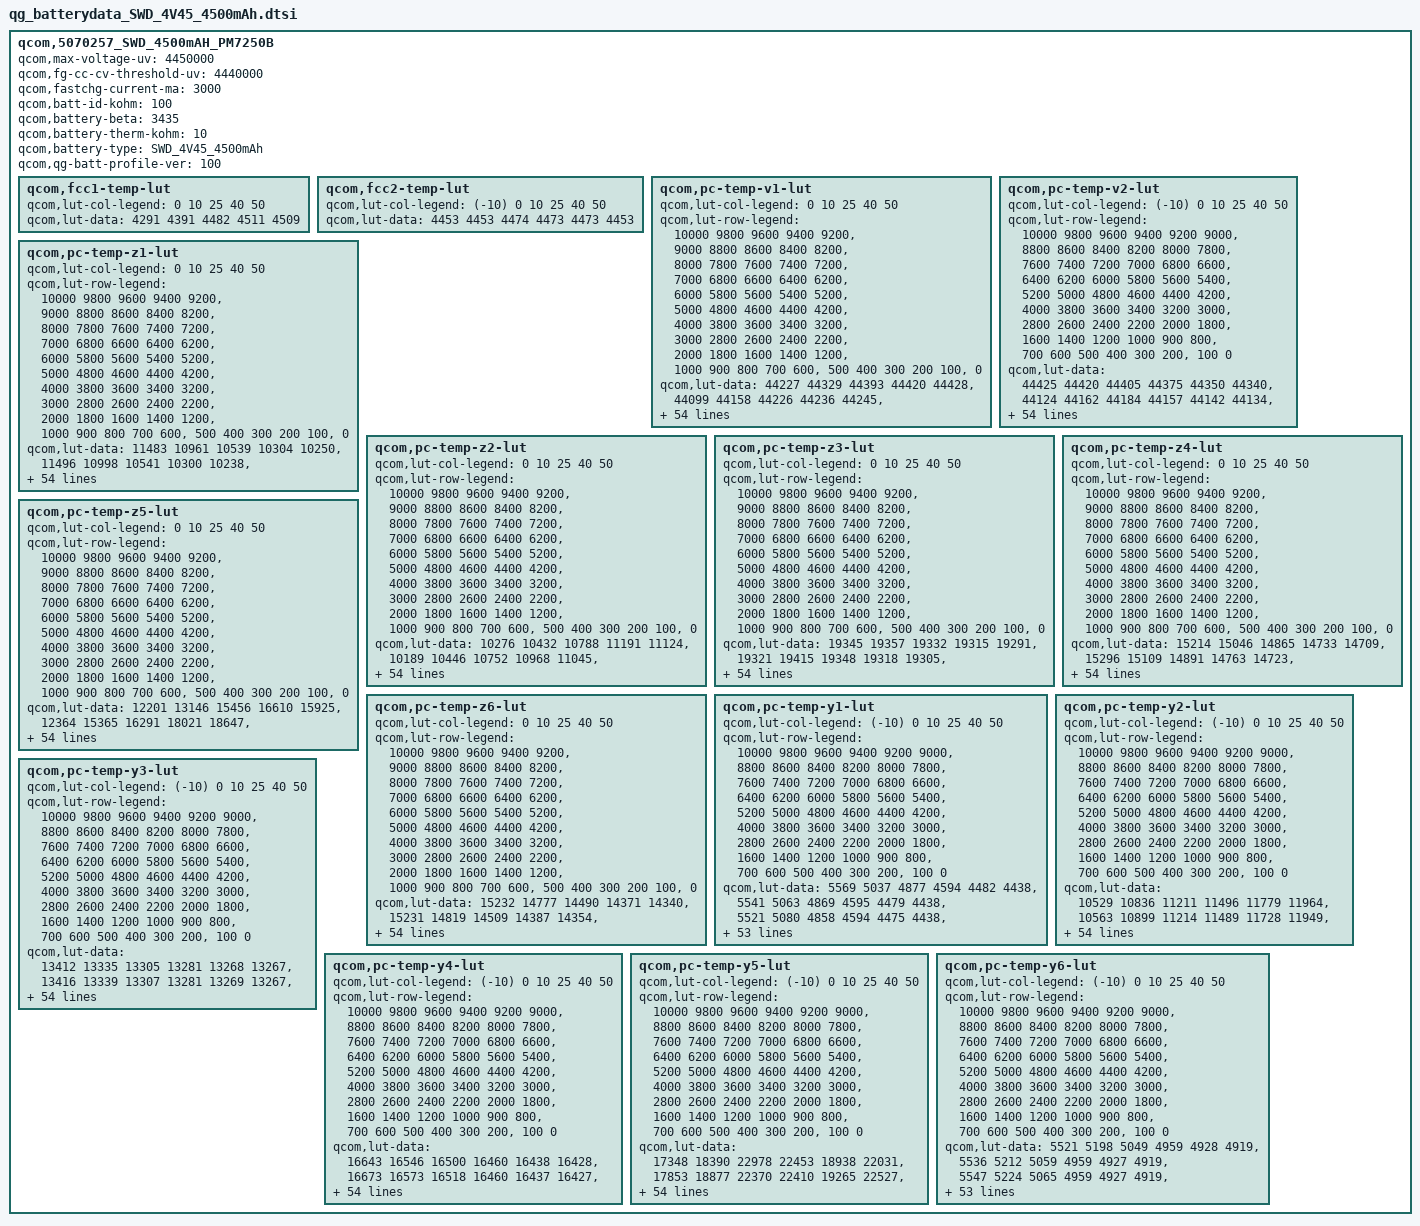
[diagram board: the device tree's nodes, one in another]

qcom,5070257_SWD_4500mAH_PM7250B {
    /* 5070257_SWD_4500mAH_PM7250B_averaged_MasterSlave_Mar23th2021 */
    qcom,max-voltage-uv = <4450000>;
    qcom,fg-cc-cv-threshold-uv = <4440000>;
    qcom,fastchg-current-ma = <3000>;
    qcom,batt-id-kohm = <100>;
    qcom,battery-beta = <3435>;
    qcom,battery-therm-kohm = <10>;
    qcom,battery-type = "SWD_4V45_4500mAh";
    qcom,qg-batt-profile-ver = <100>;

	qcom,fcc1-temp-lut {
		qcom,lut-col-legend = <0 10 25 40 50>;
		qcom,lut-data = <4291 4391 4482 4511 4509>;
	};

	qcom,fcc2-temp-lut {
		qcom,lut-col-legend = <(-10) 0 10 25 40 50>;
		qcom,lut-data = <4453 4453 4474 4473 4473 4453>;
	};

	qcom,pc-temp-v1-lut {
		qcom,lut-col-legend = <0 10 25 40 50>;
		qcom,lut-row-legend = <10000 9800 9600 9400 9200>,
			<9000 8800 8600 8400 8200>,
			<8000 7800 7600 7400 7200>,
			<7000 6800 6600 6400 6200>,
			<6000 5800 5600 5400 5200>,
			<5000 4800 4600 4400 4200>,
			<4000 3800 3600 3400 3200>,
			<3000 2800 2600 2400 2200>,
			<2000 1800 1600 1400 1200>,
			<1000 900 800 700 600>,
			<500 400 300 200 100>,
			<0>;
		qcom,lut-data = <44227 44329 44393 44420 44428>,
			<44099 44158 44226 44236 44245>,
			<43880 43973 44040 44054 44061>,
			<43653 43778 43849 43867 43876>,
			<43434 43574 43653 43675 43689>,
			<43208 43357 43446 43473 43492>,
			<42979 43129 43222 43258 43280>,
			<42744 42896 42989 43030 43054>,
			<42510 42658 42751 42797 42823>,
			<42277 42417 42508 42554 42583>,
			<42046 42178 42265 42310 42343>,
			<41821 41940 42024 42069 42105>,
			<41600 41709 41785 41830 41868>,
			<41386 41483 41551 41595 41634>,
			<41179 41264 41324 41366 41403>,
			<40978 41054 41104 41142 41177>,
			<40777 40850 40892 40924 40957>,
			<40574 40651 40686 40713 40744>,
			<40371 40464 40491 40512 40542>,
			<40169 40267 40307 40327 40354>,
			<39970 40016 40104 40132 40158>,
			<39769 39721 39849 39893 39925>,
			<39546 39485 39586 39634 39677>,
			<39314 39326 39379 39416 39460>,
			<39148 39192 39206 39231 39265>,
			<39044 39061 39055 39070 39095>,
			<38960 38937 38922 38931 38952>,
			<38869 38824 38803 38808 38827>,
			<38776 38721 38693 38694 38710>,
			<38689 38627 38591 38587 38600>,
			<38612 38541 38497 38489 38499>,
			<38539 38462 38408 38397 38405>,
			<38475 38391 38328 38313 38317>,
			<38416 38327 38259 38237 38237>,
			<38363 38271 38200 38170 38165>,
			<38317 38220 38143 38103 38090>,
			<38277 38179 38087 38031 38003>,
			<38226 38132 38029 37953 37908>,
			<38143 38056 37953 37866 37812>,
			<38036 37948 37854 37767 37713>,
			<37918 37829 37742 37657 37604>,
			<37779 37695 37616 37532 37475>,
			<37620 37545 37474 37391 37329>,
			<37437 37368 37299 37221 37162>,
			<37325 37213 37152 37087 37029>,
			<37230 37127 37068 37014 36958>,
			<37194 37103 37050 36995 36943>,
			<37165 37080 37029 36980 36928>,
			<37133 37057 37002 36957 36907>,
			<37053 36966 36895 36823 36803>,
			<36783 36648 36551 36475 36482>,
			<36324 36181 36079 36007 36042>,
			<35744 35581 35470 35403 35474>,
			<34969 34765 34644 34582 34715>,
			<33763 33484 33350 33316 33590>,
			<30000 30000 30000 30000 30000>;
	};

	qcom,pc-temp-v2-lut {
		qcom,lut-col-legend = <(-10) 0 10 25 40 50>;
		qcom,lut-row-legend = <10000 9800 9600 9400 9200 9000>,
			<8800 8600 8400 8200 8000 7800>,
			<7600 7400 7200 7000 6800 6600>,
			<6400 6200 6000 5800 5600 5400>,
			<5200 5000 4800 4600 4400 4200>,
			<4000 3800 3600 3400 3200 3000>,
			<2800 2600 2400 2200 2000 1800>,
			<1600 1400 1200 1000 900 800>,
			<700 600 500 400 300 200>,
			<100 0>;
		qcom,lut-data = <44425 44420 44405 44375 44350 44340>,
			<44124 44162 44184 44157 44142 44134>,
			<43845 43921 43969 43944 43936 43929>,
			<43590 43700 43763 43736 43732 43727>,
			<43361 43500 43567 43537 43533 43529>,
			<43135 43295 43363 43330 43327 43324>,
			<42899 43069 43141 43107 43106 43104>,
			<42660 42832 42907 42873 42874 42876>,
			<42416 42594 42670 42636 42640 42644>,
			<42165 42351 42429 42394 42399 42405>,
			<41913 42108 42187 42152 42158 42166>,
			<41654 41868 41948 41912 41920 41929>,
			<41400 41631 41710 41674 41684 41694>,
			<41203 41397 41476 41442 41451 41463>,
			<41066 41165 41246 41215 41223 41237>,
			<40916 40945 41022 40994 41001 41015>,
			<40671 40760 40810 40779 40787 40800>,
			<40351 40589 40605 40569 40579 40591>,
			<40056 40377 40392 40367 40379 40391>,
			<39784 40093 40175 40178 40192 40207>,
			<39528 39800 39946 39975 39993 40013>,
			<39289 39546 39684 39719 39741 39767>,
			<39065 39309 39412 39435 39461 39488>,
			<38861 39102 39190 39209 39238 39262>,
			<38666 38920 39009 39032 39062 39088>,
			<38499 38758 38850 38878 38909 38938>,
			<38378 38614 38710 38740 38774 38802>,
			<38281 38484 38584 38617 38653 38680>,
			<38201 38360 38467 38505 38541 38566>,
			<38135 38233 38357 38401 38438 38459>,
			<38078 38121 38256 38305 38343 38360>,
			<38019 38039 38162 38214 38254 38271>,
			<37964 37974 38075 38129 38172 38190>,
			<37907 37919 37994 38048 38089 38105>,
			<37852 37876 37920 37975 38006 38015>,
			<37794 37837 37851 37900 37917 37917>,
			<37728 37794 37789 37809 37808 37802>,
			<37655 37751 37732 37708 37684 37666>,
			<37574 37695 37662 37610 37572 37542>,
			<37482 37616 37577 37519 37477 37443>,
			<37377 37513 37476 37424 37379 37348>,
			<37255 37381 37354 37313 37264 37234>,
			<37111 37205 37211 37187 37134 37102>,
			<36981 37030 37047 37029 36976 36954>,
			<36867 36877 36920 36912 36871 36831>,
			<36781 36797 36858 36875 36845 36803>,
			<36741 36771 36835 36860 36830 36790>,
			<36696 36736 36804 36835 36809 36772>,
			<36633 36692 36756 36793 36768 36738>,
			<36497 36576 36626 36673 36623 36629>,
			<36199 36288 36287 36336 36258 36295>,
			<35750 35841 35780 35838 35755 35826>,
			<35122 35227 35113 35196 35109 35227>,
			<34249 34398 34203 34344 34230 34434>,
			<32871 33127 32802 33051 32965 33306>,
			<29691 30594 29626 29434 29627 31317>;
	};

	qcom,pc-temp-z1-lut {
		qcom,lut-col-legend = <0 10 25 40 50>;
		qcom,lut-row-legend = <10000 9800 9600 9400 9200>,
			<9000 8800 8600 8400 8200>,
			<8000 7800 7600 7400 7200>,
			<7000 6800 6600 6400 6200>,
			<6000 5800 5600 5400 5200>,
			<5000 4800 4600 4400 4200>,
			<4000 3800 3600 3400 3200>,
			<3000 2800 2600 2400 2200>,
			<2000 1800 1600 1400 1200>,
			<1000 900 800 700 600>,
			<500 400 300 200 100>,
			<0>;
		qcom,lut-data = <11483 10961 10539 10304 10250>,
			<11496 10998 10541 10300 10238>,
			<11471 10996 10529 10298 10238>,
			<11463 10980 10520 10295 10237>,
			<11466 10960 10512 10291 10236>,
			<11467 10938 10504 10288 10234>,
			<11457 10917 10493 10285 10233>,
			<11431 10907 10483 10282 10232>,
			<11403 10900 10478 10280 10231>,
			<11375 10895 10475 10278 10229>,
			<11343 10888 10472 10276 10227>,
			<11326 10881 10469 10274 10227>,
			<11319 10878 10466 10273 10227>,
			<11314 10878 10464 10272 10227>,
			<11313 10877 10462 10271 10226>,
			<11314 10872 10461 10271 10225>,
			<11315 10865 10460 10271 10225>,
			<11313 10861 10460 10271 10227>,
			<11309 10859 10460 10271 10228>,
			<11310 10857 10462 10271 10227>,
			<11314 10856 10463 10270 10227>,
			<11318 10859 10464 10271 10227>,
			<11315 10862 10465 10271 10228>,
			<11309 10863 10467 10272 10228>,
			<11306 10864 10472 10274 10229>,
			<11313 10864 10477 10276 10229>,
			<11320 10862 10481 10278 10231>,
			<11320 10861 10483 10280 10234>,
			<11316 10867 10486 10282 10236>,
			<11313 10874 10490 10284 10236>,
			<11321 10875 10493 10286 10237>,
			<11337 10876 10497 10288 10238>,
			<11340 10879 10500 10291 10240>,
			<11329 10884 10504 10293 10242>,
			<11318 10891 10508 10296 10243>,
			<11321 10895 10512 10298 10245>,
			<11333 10899 10517 10301 10248>,
			<11341 10903 10523 10304 10250>,
			<11339 10907 10528 10307 10252>,
			<11336 10917 10533 10309 10253>,
			<11338 10920 10537 10311 10254>,
			<11344 10914 10539 10310 10255>,
			<11356 10911 10542 10310 10255>,
			<11376 10928 10547 10312 10255>,
			<11368 10938 10556 10315 10256>,
			<11372 10949 10558 10316 10257>,
			<11374 10929 10559 10315 10255>,
			<11360 10940 10557 10316 10255>,
			<11378 10948 10560 10318 10257>,
			<11405 10957 10568 10320 10259>,
			<11404 10939 10566 10321 10259>,
			<11405 10972 10576 10325 10260>,
			<11423 10970 10586 10329 10264>,
			<11416 10967 10587 10333 10267>,
			<11416 10967 10587 10333 10267>,
			<11416 10967 10587 10333 10267>;
	};

	qcom,pc-temp-z2-lut {
		qcom,lut-col-legend = <0 10 25 40 50>;
		qcom,lut-row-legend = <10000 9800 9600 9400 9200>,
			<9000 8800 8600 8400 8200>,
			<8000 7800 7600 7400 7200>,
			<7000 6800 6600 6400 6200>,
			<6000 5800 5600 5400 5200>,
			<5000 4800 4600 4400 4200>,
			<4000 3800 3600 3400 3200>,
			<3000 2800 2600 2400 2200>,
			<2000 1800 1600 1400 1200>,
			<1000 900 800 700 600>,
			<500 400 300 200 100>,
			<0>;
		qcom,lut-data = <10276 10432 10788 11191 11124>,
			<10189 10446 10752 10968 11045>,
			<10279 10474 10771 10906 11065>,
			<10336 10510 10759 10906 11050>,
			<10335 10522 10731 10892 10973>,
			<10332 10499 10722 10876 10916>,
			<10323 10462 10717 10864 10924>,
			<10301 10439 10707 10843 10940>,
			<10279 10423 10696 10828 10947>,
			<10264 10417 10681 10833 10959>,
			<10252 10431 10670 10850 10972>,
			<10250 10452 10673 10859 10977>,
			<10272 10460 10687 10859 10979>,
			<10299 10461 10692 10860 10988>,
			<10314 10463 10688 10875 11017>,
			<10324 10475 10684 10895 11041>,
			<10333 10493 10683 10917 11046>,
			<10340 10498 10685 10939 11049>,
			<10346 10501 10693 10941 11058>,
			<10352 10503 10708 10933 11075>,
			<10359 10507 10713 10930 11091>,
			<10363 10509 10717 10957 11120>,
			<10354 10505 10725 10993 11156>,
			<10335 10499 10743 10985 11138>,
			<10327 10500 10778 10877 11000>,
			<10333 10507 10792 10777 10884>,
			<10344 10517 10749 10749 10854>,
			<10352 10519 10690 10736 10836>,
			<10361 10508 10679 10742 10838>,
			<10369 10496 10681 10763 10876>,
			<10374 10496 10685 10785 10925>,
			<10379 10511 10702 10803 10970>,
			<10386 10529 10722 10826 11021>,
			<10398 10544 10734 10865 11071>,
			<10409 10558 10753 10938 11127>,
			<10410 10562 10768 10991 11180>,
			<10411 10561 10782 11008 11241>,
			<10412 10560 10803 11023 11297>,
			<10424 10574 10829 11048 11304>,
			<10438 10601 10876 11105 11280>,
			<10439 10610 10902 11141 11260>,
			<10429 10583 10890 11110 11253>,
			<10426 10569 10871 11066 11236>,
			<10435 10577 10852 11028 11153>,
			<11496 10658 10865 11038 11127>,
			<16946 10662 10864 11045 11112>,
			<16875 10644 10839 11067 11205>,
			<18706 10638 10782 11122 11277>,
			<18966 10661 10795 11145 11438>,
			<17819 10699 10840 11038 11138>,
			<17294 10780 10804 10876 10990>,
			<16141 10854 10728 10822 10887>,
			<15024 10936 10675 10769 10866>,
			<13292 10886 10696 10710 10806>,
			<13292 10886 10696 10710 10806>,
			<13292 10886 10696 10710 10806>;
	};

	qcom,pc-temp-z3-lut {
		qcom,lut-col-legend = <0 10 25 40 50>;
		qcom,lut-row-legend = <10000 9800 9600 9400 9200>,
			<9000 8800 8600 8400 8200>,
			<8000 7800 7600 7400 7200>,
			<7000 6800 6600 6400 6200>,
			<6000 5800 5600 5400 5200>,
			<5000 4800 4600 4400 4200>,
			<4000 3800 3600 3400 3200>,
			<3000 2800 2600 2400 2200>,
			<2000 1800 1600 1400 1200>,
			<1000 900 800 700 600>,
			<500 400 300 200 100>,
			<0>;
		qcom,lut-data = <19345 19357 19332 19315 19291>,
			<19321 19415 19348 19318 19305>,
			<19482 19449 19368 19328 19316>,
			<19575 19471 19380 19337 19321>,
			<19598 19484 19388 19343 19323>,
			<19612 19492 19392 19345 19323>,
			<19617 19497 19392 19343 19323>,
			<19620 19497 19392 19337 19323>,
			<19622 19495 19390 19334 19322>,
			<19623 19493 19384 19333 19321>,
			<19622 19488 19379 19333 19319>,
			<19620 19484 19377 19332 19316>,
			<19612 19480 19375 19330 19312>,
			<19601 19477 19373 19327 19310>,
			<19594 19474 19370 19323 19309>,
			<19588 19470 19366 19319 19308>,
			<19586 19467 19363 19317 19307>,
			<19586 19463 19360 19317 19306>,
			<19587 19459 19359 19316 19305>,
			<19589 19457 19360 19314 19303>,
			<19590 19463 19360 19313 19302>,
			<19591 19479 19360 19315 19306>,
			<19592 19485 19361 19321 19315>,
			<19593 19470 19365 19327 19322>,
			<19593 19453 19379 19336 19329>,
			<19589 19456 19389 19341 19332>,
			<19584 19476 19392 19341 19330>,
			<19584 19487 19394 19340 19325>,
			<19585 19484 19392 19339 19322>,
			<19586 19478 19386 19335 19318>,
			<19584 19474 19380 19330 19314>,
			<19580 19469 19378 19328 19311>,
			<19577 19466 19376 19325 19309>,
			<19573 19463 19372 19322 19306>,
			<19570 19460 19368 19319 19303>,
			<19567 19459 19366 19317 19301>,
			<19565 19458 19367 19318 19302>,
			<19562 19456 19368 19319 19304>,
			<19555 19453 19367 19321 19306>,
			<19547 19446 19365 19323 19308>,
			<19541 19441 19362 19325 19311>,
			<19538 19439 19359 19323 19313>,
			<19533 19436 19357 19320 19314>,
			<19524 19429 19356 19323 19314>,
			<19297 19414 19349 19319 19312>,
			<19257 19405 19345 19313 19306>,
			<19257 19403 19338 19311 19297>,
			<19256 19403 19337 19307 19295>,
			<19256 19390 19336 19301 19292>,
			<19256 19389 19338 19315 19301>,
			<19256 19380 19350 19319 19306>,
			<19257 19361 19353 19321 19305>,
			<19257 19340 19355 19322 19306>,
			<19257 19331 19344 19323 19308>,
			<19257 19331 19344 19323 19308>,
			<19257 19331 19344 19323 19308>;
	};

	qcom,pc-temp-z4-lut {
		qcom,lut-col-legend = <0 10 25 40 50>;
		qcom,lut-row-legend = <10000 9800 9600 9400 9200>,
			<9000 8800 8600 8400 8200>,
			<8000 7800 7600 7400 7200>,
			<7000 6800 6600 6400 6200>,
			<6000 5800 5600 5400 5200>,
			<5000 4800 4600 4400 4200>,
			<4000 3800 3600 3400 3200>,
			<3000 2800 2600 2400 2200>,
			<2000 1800 1600 1400 1200>,
			<1000 900 800 700 600>,
			<500 400 300 200 100>,
			<0>;
		qcom,lut-data = <15214 15046 14865 14733 14709>,
			<15296 15109 14891 14763 14723>,
			<15277 15102 14882 14761 14722>,
			<15250 15045 14861 14752 14719>,
			<15182 14980 14821 14731 14704>,
			<15093 14925 14785 14710 14688>,
			<15023 14875 14753 14698 14678>,
			<14962 14834 14728 14690 14670>,
			<14911 14796 14718 14684 14664>,
			<14871 14769 14714 14678 14661>,
			<14838 14756 14708 14672 14658>,
			<14812 14747 14702 14667 14655>,
			<14789 14742 14695 14662 14653>,
			<14773 14738 14689 14658 14649>,
			<14770 14736 14684 14655 14644>,
			<14769 14732 14681 14652 14640>,
			<14768 14729 14679 14647 14635>,
			<14774 14729 14677 14642 14630>,
			<14786 14732 14674 14639 14627>,
			<14795 14739 14672 14637 14624>,
			<14802 14761 14673 14637 14623>,
			<14811 14812 14715 14658 14637>,
			<14838 14842 14771 14698 14663>,
			<14882 14848 14777 14708 14669>,
			<14899 14851 14763 14701 14666>,
			<14881 14842 14747 14692 14662>,
			<14856 14805 14731 14683 14660>,
			<14839 14778 14716 14674 14656>,
			<14826 14769 14708 14668 14653>,
			<14818 14763 14703 14664 14650>,
			<14816 14762 14700 14660 14646>,
			<14814 14762 14698 14656 14643>,
			<14813 14763 14697 14653 14640>,
			<14813 14764 14697 14652 14638>,
			<14812 14765 14698 14652 14637>,
			<14810 14766 14700 14653 14636>,
			<14806 14763 14704 14659 14643>,
			<14802 14760 14710 14671 14655>,
			<14796 14757 14710 14673 14657>,
			<14787 14754 14710 14670 14652>,
			<14775 14747 14708 14667 14647>,
			<14756 14732 14698 14661 14642>,
			<14735 14715 14684 14656 14638>,
			<14714 14701 14676 14652 14637>,
			<14870 14671 14662 14646 14633>,
			<14891 14654 14646 14635 14626>,
			<14887 14645 14638 14627 14625>,
			<14884 14639 14628 14622 14617>,
			<14878 14645 14625 14620 14613>,
			<14876 14649 14630 14617 14612>,
			<14878 14663 14624 14618 14614>,
			<14882 14685 14620 14616 14615>,
			<14883 14708 14618 14615 14614>,
			<14886 14721 14628 14616 14612>,
			<14886 14721 14628 14616 14612>,
			<14886 14721 14628 14616 14612>;
	};

	qcom,pc-temp-z5-lut {
		qcom,lut-col-legend = <0 10 25 40 50>;
		qcom,lut-row-legend = <10000 9800 9600 9400 9200>,
			<9000 8800 8600 8400 8200>,
			<8000 7800 7600 7400 7200>,
			<7000 6800 6600 6400 6200>,
			<6000 5800 5600 5400 5200>,
			<5000 4800 4600 4400 4200>,
			<4000 3800 3600 3400 3200>,
			<3000 2800 2600 2400 2200>,
			<2000 1800 1600 1400 1200>,
			<1000 900 800 700 600>,
			<500 400 300 200 100>,
			<0>;
		qcom,lut-data = <12201 13146 15456 16610 15925>,
			<12364 15365 16291 18021 18647>,
			<15215 17021 17797 19534 21225>,
			<17512 18271 18664 20627 22012>,
			<18779 19303 19192 21380 22112>,
			<19845 20239 19853 21745 22229>,
			<20990 21139 21014 21700 22927>,
			<22148 22184 21986 21480 24107>,
			<23424 23524 22037 21416 24570>,
			<24991 24890 21763 21907 24723>,
			<26743 26070 21624 22568 24779>,
			<28473 27104 22052 23052 24223>,
			<30581 27749 22779 23456 23170>,
			<32189 28164 23215 23507 22980>,
			<32476 28524 23445 22827 23715>,
			<32541 28943 23406 22178 24600>,
			<32677 29302 23234 22709 25627>,
			<34836 29295 23347 23918 27104>,
			<37933 28658 24167 24754 28366>,
			<38409 28071 25812 25382 29729>,
			<36669 30916 26653 25691 30499>,
			<35156 37924 25006 23766 28084>,
			<35209 40389 22323 20293 23616>,
			<35545 32530 21433 19415 22556>,
			<35577 23441 21090 19597 22892>,
			<33964 23095 21014 19915 23136>,
			<32074 26714 22436 20951 23318>,
			<32332 30188 24850 22658 23694>,
			<34946 32383 26470 23798 23874>,
			<37600 34252 27686 24515 24367>,
			<39353 35907 29161 25348 24978>,
			<40892 37484 31956 26909 25819>,
			<41778 38662 34715 28838 27012>,
			<42405 39408 35582 30241 28052>,
			<42768 39964 35988 31461 29137>,
			<42739 40040 36217 32068 29704>,
			<42549 39753 36341 31219 28615>,
			<42322 39318 36419 29767 26762>,
			<41786 38239 35752 29503 26649>,
			<41146 36084 32558 29932 28796>,
			<40947 34948 30175 30245 31634>,
			<40919 34742 29770 29679 35540>,
			<40996 34365 29480 29046 38344>,
			<41297 32504 27986 29599 37333>,
			<15996 36567 27844 27311 33293>,
			<11520 36362 30829 26536 28949>,
			<11465 35846 28815 30108 24360>,
			<11413 38680 33083 33526 29376>,
			<11381 27120 33248 29161 32387>,
			<11386 25819 27961 38977 38496>,
			<11427 20698 33144 36361 37762>,
			<11382 16616 35473 39815 35624>,
			<11352 14381 37768 40149 34964>,
			<11276 13730 28173 39394 36724>,
			<11276 13730 28173 39394 36724>,
			<11276 13730 28173 39394 36724>;
	};

	qcom,pc-temp-z6-lut {
		qcom,lut-col-legend = <0 10 25 40 50>;
		qcom,lut-row-legend = <10000 9800 9600 9400 9200>,
			<9000 8800 8600 8400 8200>,
			<8000 7800 7600 7400 7200>,
			<7000 6800 6600 6400 6200>,
			<6000 5800 5600 5400 5200>,
			<5000 4800 4600 4400 4200>,
			<4000 3800 3600 3400 3200>,
			<3000 2800 2600 2400 2200>,
			<2000 1800 1600 1400 1200>,
			<1000 900 800 700 600>,
			<500 400 300 200 100>,
			<0>;
		qcom,lut-data = <15232 14777 14490 14371 14340>,
			<15231 14819 14509 14387 14354>,
			<15242 14818 14511 14391 14358>,
			<15246 14793 14507 14391 14358>,
			<15203 14762 14491 14385 14353>,
			<15133 14732 14475 14377 14347>,
			<15078 14702 14460 14370 14342>,
			<15028 14675 14447 14363 14338>,
			<14984 14649 14439 14358 14334>,
			<14949 14629 14433 14354 14332>,
			<14918 14617 14428 14351 14329>,
			<14892 14608 14423 14348 14326>,
			<14867 14602 14419 14345 14323>,
			<14849 14597 14414 14341 14320>,
			<14841 14592 14410 14337 14318>,
			<14836 14588 14407 14334 14315>,
			<14834 14583 14403 14331 14312>,
			<14835 14582 14401 14328 14310>,
			<14839 14581 14400 14326 14308>,
			<14842 14581 14399 14325 14306>,
			<14844 14592 14399 14324 14305>,
			<14848 14624 14418 14335 14313>,
			<14861 14639 14443 14356 14330>,
			<14881 14636 14449 14363 14336>,
			<14889 14631 14450 14364 14339>,
			<14881 14627 14451 14365 14340>,
			<14869 14623 14447 14363 14338>,
			<14864 14619 14442 14358 14334>,
			<14860 14614 14437 14354 14331>,
			<14859 14609 14432 14350 14327>,
			<14858 14608 14429 14346 14324>,
			<14857 14607 14427 14343 14321>,
			<14857 14607 14426 14341 14318>,
			<14857 14607 14426 14339 14316>,
			<14857 14608 14425 14338 14313>,
			<14858 14608 14425 14337 14312>,
			<14860 14610 14428 14341 14316>,
			<14860 14612 14433 14347 14323>,
			<14860 14612 14433 14349 14324>,
			<14859 14611 14433 14349 14324>,
			<14857 14609 14432 14349 14323>,
			<14854 14605 14427 14345 14322>,
			<14852 14601 14422 14342 14321>,
			<14850 14597 14419 14342 14321>,
			<14819 14583 14411 14338 14318>,
			<14811 14576 14403 14330 14312>,
			<14813 14571 14396 14325 14307>,
			<14815 14569 14392 14321 14302>,
			<14816 14567 14391 14317 14298>,
			<14821 14575 14396 14324 14303>,
			<14829 14579 14401 14327 14308>,
			<14838 14583 14402 14328 14308>,
			<14847 14587 14405 14329 14309>,
			<14860 14596 14406 14331 14310>,
			<14860 14596 14406 14331 14310>,
			<14860 14596 14406 14331 14310>;
	};

	qcom,pc-temp-y1-lut {
		qcom,lut-col-legend = <(-10) 0 10 25 40 50>;
		qcom,lut-row-legend = <10000 9800 9600 9400 9200 9000>,
			<8800 8600 8400 8200 8000 7800>,
			<7600 7400 7200 7000 6800 6600>,
			<6400 6200 6000 5800 5600 5400>,
			<5200 5000 4800 4600 4400 4200>,
			<4000 3800 3600 3400 3200 3000>,
			<2800 2600 2400 2200 2000 1800>,
			<1600 1400 1200 1000 900 800>,
			<700 600 500 400 300 200>,
			<100 0>;
		qcom,lut-data = <5569 5037 4877 4594 4482 4438>,
			<5541 5063 4869 4595 4479 4438>,
			<5521 5080 4858 4594 4475 4438>,
			<5506 5092 4847 4593 4472 4438>,
			<5498 5098 4838 4591 4470 4438>,
			<5495 5102 4835 4588 4468 4438>,
			<5501 5100 4836 4584 4467 4437>,
			<5512 5094 4838 4580 4466 4435>,
			<5514 5091 4836 4578 4465 4433>,
			<5504 5086 4822 4576 4463 4432>,
			<5496 5081 4811 4575 4461 4431>,
			<5496 5082 4810 4573 4460 4431>,
			<5499 5084 4811 4571 4459 4432>,
			<5502 5084 4810 4569 4459 4432>,
			<5509 5078 4809 4567 4459 4432>,
			<5514 5074 4809 4566 4458 4432>,
			<5515 5075 4808 4566 4457 4431>,
			<5513 5079 4807 4566 4456 4430>,
			<5510 5083 4806 4567 4456 4430>,
			<5503 5090 4806 4568 4457 4430>,
			<5497 5095 4806 4568 4458 4431>,
			<5495 5095 4806 4569 4458 4432>,
			<5493 5094 4808 4571 4459 4432>,
			<5494 5093 4809 4573 4459 4433>,
			<5498 5094 4810 4574 4459 4433>,
			<5504 5094 4811 4576 4460 4433>,
			<5510 5093 4812 4578 4460 4434>,
			<5515 5092 4814 4580 4461 4435>,
			<5516 5092 4816 4583 4462 4435>,
			<5508 5096 4819 4585 4464 4436>,
			<5499 5101 4821 4587 4465 4437>,
			<5497 5104 4822 4589 4466 4437>,
			<5496 5106 4824 4591 4467 4438>,
			<5497 5108 4825 4593 4468 4438>,
			<5507 5113 4825 4597 4470 4440>,
			<5517 5117 4824 4601 4471 4441>,
			<5514 5114 4829 4604 4473 4441>,
			<5499 5105 4837 4606 4474 4442>,
			<5491 5100 4840 4608 4475 4443>,
			<5499 5100 4836 4610 4475 4443>,
			<5508 5101 4833 4613 4475 4443>,
			<5510 5103 4846 4616 4477 4445>,
			<5509 5110 4860 4618 4479 4447>,
			<5503 5108 4861 4619 4480 4447>,
			<5495 5103 4863 4623 4480 4446>,
			<5521 5132 4873 4629 4483 4446>,
			<5505 5120 4858 4630 4483 4449>,
			<5501 5130 4877 4631 4484 4449>,
			<5512 5116 4884 4633 4484 4448>,
			<5521 5114 4866 4634 4482 4449>,
			<5539 5133 4882 4638 4482 4449>,
			<5588 5131 4873 4638 4484 4447>,
			<5624 5149 4887 4645 4485 4451>,
			<5651 5152 4893 4653 4488 4452>,
			<5651 5152 4893 4653 4488 4452>,
			<5651 5152 4893 4653 4488 4452>;
	};

	qcom,pc-temp-y2-lut {
		qcom,lut-col-legend = <(-10) 0 10 25 40 50>;
		qcom,lut-row-legend = <10000 9800 9600 9400 9200 9000>,
			<8800 8600 8400 8200 8000 7800>,
			<7600 7400 7200 7000 6800 6600>,
			<6400 6200 6000 5800 5600 5400>,
			<5200 5000 4800 4600 4400 4200>,
			<4000 3800 3600 3400 3200 3000>,
			<2800 2600 2400 2200 2000 1800>,
			<1600 1400 1200 1000 900 800>,
			<700 600 500 400 300 200>,
			<100 0>;
		qcom,lut-data = <10529 10836 11211 11496 11779 11964>,
			<10563 10899 11214 11489 11728 11949>,
			<10614 10940 11207 11458 11667 11918>,
			<10669 10965 11193 11415 11605 11875>,
			<10716 10976 11175 11375 11554 11829>,
			<10741 10979 11154 11351 11522 11786>,
			<10748 10965 11126 11330 11506 11739>,
			<10753 10940 11094 11300 11496 11684>,
			<10753 10929 11076 11278 11486 11629>,
			<10746 10921 11062 11256 11458 11566>,
			<10741 10916 11054 11238 11434 11521>,
			<10771 10923 11053 11229 11416 11513>,
			<10836 10940 11055 11224 11395 11519>,
			<10869 10959 11062 11231 11391 11516>,
			<10882 10981 11089 11263 11398 11498>,
			<10895 11011 11128 11303 11403 11483>,
			<10927 11063 11185 11335 11415 11493>,
			<10969 11131 11254 11370 11449 11521>,
			<10978 11157 11302 11432 11501 11551>,
			<10949 11164 11346 11574 11609 11585>,
			<10911 11165 11371 11675 11691 11626>,
			<10887 11148 11346 11624 11684 11691>,
			<10865 11109 11301 11513 11647 11780>,
			<10831 11090 11289 11478 11652 11841>,
			<10636 11097 11295 11478 11718 11878>,
			<10416 11107 11305 11478 11771 11906>,
			<10218 11109 11318 11492 11791 11934>,
			<9874 11112 11334 11516 11819 11967>,
			<9732 11112 11338 11529 11845 12006>,
			<9723 11111 11334 11540 11869 12084>,
			<9717 11110 11331 11552 11896 12152>,
			<9710 11114 11338 11572 11942 12145>,
			<9703 11127 11351 11608 12005 12106>,
			<9697 11132 11354 11627 12022 12089>,
			<9691 11098 11351 11632 11953 12114>,
			<9685 11045 11345 11635 11886 12144>,
			<9681 11007 11332 11619 11880 12145>,
			<9678 10974 11302 11575 11882 12127>,
			<9675 10932 11273 11554 11886 12107>,
			<9673 10881 11252 11556 11867 12083>,
			<9672 10804 11225 11557 11830 12050>,
			<9670 10543 11163 11549 11840 11996>,
			<9669 9962 11068 11524 11899 11918>,
			<9667 9776 10961 11451 11889 11944>,
			<9666 9722 10847 11425 11826 12028>,
			<9665 9699 10806 11441 11730 11775>,
			<9664 9694 10776 11465 11679 11759>,
			<9663 9688 10755 11394 11644 11641>,
			<9662 9683 10718 11416 11541 11562>,
			<9660 9677 10696 11334 11517 11540>,
			<9658 9672 10613 11343 11526 11591>,
			<9656 9668 10496 11282 11485 11491>,
			<9652 9664 10223 11180 11415 11465>,
			<9650 9659 9895 11178 11324 11344>,
			<9650 9659 9895 11178 11324 11344>,
			<9650 9659 9895 11178 11324 11344>;
	};

	qcom,pc-temp-y3-lut {
		qcom,lut-col-legend = <(-10) 0 10 25 40 50>;
		qcom,lut-row-legend = <10000 9800 9600 9400 9200 9000>,
			<8800 8600 8400 8200 8000 7800>,
			<7600 7400 7200 7000 6800 6600>,
			<6400 6200 6000 5800 5600 5400>,
			<5200 5000 4800 4600 4400 4200>,
			<4000 3800 3600 3400 3200 3000>,
			<2800 2600 2400 2200 2000 1800>,
			<1600 1400 1200 1000 900 800>,
			<700 600 500 400 300 200>,
			<100 0>;
		qcom,lut-data = <13412 13335 13305 13281 13268 13267>,
			<13416 13339 13307 13281 13269 13267>,
			<13420 13344 13309 13282 13270 13268>,
			<13423 13348 13311 13282 13270 13268>,
			<13427 13352 13313 13283 13271 13269>,
			<13430 13354 13314 13283 13272 13269>,
			<13433 13356 13314 13283 13273 13270>,
			<13435 13357 13315 13284 13273 13270>,
			<13435 13358 13316 13284 13274 13271>,
			<13432 13360 13317 13285 13275 13271>,
			<13429 13362 13318 13285 13275 13272>,
			<13426 13362 13319 13285 13275 13272>,
			<13423 13362 13320 13285 13276 13273>,
			<13419 13361 13320 13286 13276 13273>,
			<13407 13356 13320 13288 13276 13273>,
			<13399 13350 13319 13290 13276 13274>,
			<13400 13347 13317 13290 13277 13273>,
			<13403 13344 13314 13290 13279 13273>,
			<13403 13343 13313 13290 13280 13273>,
			<13393 13341 13314 13291 13281 13275>,
			<13380 13339 13314 13291 13281 13276>,
			<13374 13336 13312 13289 13279 13275>,
			<13370 13332 13307 13285 13275 13271>,
			<13364 13328 13304 13282 13272 13269>,
			<13355 13326 13302 13282 13271 13269>,
			<13347 13324 13301 13281 13270 13268>,
			<13345 13323 13301 13281 13270 13268>,
			<13343 13322 13300 13280 13270 13268>,
			<13344 13321 13300 13280 13270 13268>,
			<13351 13317 13300 13280 13271 13268>,
			<13362 13313 13299 13281 13272 13268>,
			<13371 13311 13298 13281 13272 13268>,
			<13378 13310 13298 13280 13271 13269>,
			<13389 13310 13297 13280 13271 13269>,
			<13404 13313 13297 13280 13271 13269>,
			<13425 13317 13297 13280 13271 13269>,
			<13448 13321 13298 13280 13271 13269>,
			<13476 13324 13298 13279 13270 13268>,
			<13507 13327 13298 13278 13269 13268>,
			<13540 13330 13298 13276 13270 13268>,
			<13577 13333 13299 13275 13270 13268>,
			<13620 13337 13299 13276 13270 13269>,
			<13669 13341 13300 13278 13271 13269>,
			<13725 13351 13303 13278 13270 13269>,
			<13792 13372 13306 13279 13270 13268>,
			<13882 13394 13308 13279 13271 13269>,
			<13907 13400 13309 13281 13272 13270>,
			<13981 13416 13312 13281 13273 13271>,
			<14070 13449 13318 13285 13275 13272>,
			<14185 13484 13326 13287 13275 13271>,
			<14337 13526 13327 13286 13274 13271>,
			<14682 13610 13334 13287 13274 13271>,
			<15761 13749 13347 13289 13275 13271>,
			<18160 14068 13379 13293 13276 13272>,
			<18160 14068 13379 13293 13276 13272>,
			<18160 14068 13379 13293 13276 13272>;
	};

	qcom,pc-temp-y4-lut {
		qcom,lut-col-legend = <(-10) 0 10 25 40 50>;
		qcom,lut-row-legend = <10000 9800 9600 9400 9200 9000>,
			<8800 8600 8400 8200 8000 7800>,
			<7600 7400 7200 7000 6800 6600>,
			<6400 6200 6000 5800 5600 5400>,
			<5200 5000 4800 4600 4400 4200>,
			<4000 3800 3600 3400 3200 3000>,
			<2800 2600 2400 2200 2000 1800>,
			<1600 1400 1200 1000 900 800>,
			<700 600 500 400 300 200>,
			<100 0>;
		qcom,lut-data = <16643 16546 16500 16460 16438 16428>,
			<16673 16573 16518 16460 16437 16427>,
			<16737 16618 16538 16460 16435 16426>,
			<16813 16669 16556 16461 16434 16425>,
			<16877 16711 16571 16461 16433 16424>,
			<16906 16729 16576 16461 16432 16424>,
			<16908 16728 16574 16461 16431 16423>,
			<16909 16724 16569 16461 16431 16423>,
			<16909 16719 16566 16462 16431 16424>,
			<16910 16711 16562 16464 16432 16424>,
			<16911 16706 16560 16466 16434 16425>,
			<16914 16708 16561 16470 16436 16426>,
			<16921 16715 16564 16475 16439 16427>,
			<16944 16725 16569 16479 16442 16429>,
			<17065 16748 16581 16482 16447 16432>,
			<17163 16780 16599 16487 16452 16436>,
			<17114 16835 16634 16496 16456 16440>,
			<16986 16904 16679 16510 16460 16446>,
			<16892 16917 16692 16529 16468 16453>,
			<16828 16837 16691 16564 16488 16466>,
			<16772 16740 16686 16587 16503 16476>,
			<16719 16683 16644 16562 16491 16468>,
			<16670 16637 16570 16507 16464 16448>,
			<16633 16605 16532 16478 16449 16437>,
			<16599 16582 16514 16464 16441 16432>,
			<16577 16564 16505 16457 16438 16430>,
			<16586 16552 16502 16458 16438 16430>,
			<16615 16542 16501 16459 16439 16431>,
			<16626 16530 16501 16461 16441 16433>,
			<16625 16509 16501 16466 16444 16435>,
			<16623 16492 16501 16471 16448 16439>,
			<16625 16492 16501 16476 16454 16443>,
			<16633 16496 16502 16482 16462 16450>,
			<16641 16501 16502 16486 16466 16453>,
			<16647 16512 16497 16490 16468 16452>,
			<16652 16526 16492 16493 16468 16451>,
			<16659 16544 16493 16485 16462 16447>,
			<16666 16569 16496 16464 16447 16437>,
			<16671 16584 16497 16453 16440 16432>,
			<16673 16591 16498 16449 16438 16432>,
			<16675 16595 16499 16447 16437 16432>,
			<16669 16594 16504 16447 16434 16431>,
			<16648 16588 16513 16447 16431 16429>,
			<16645 16580 16518 16446 16425 16425>,
			<16647 16574 16524 16447 16423 16420>,
			<16660 16585 16525 16454 16429 16424>,
			<16660 16586 16528 16455 16431 16425>,
			<16684 16605 16541 16464 16435 16430>,
			<16711 16631 16561 16471 16448 16446>,
			<16727 16653 16579 16482 16451 16460>,
			<16719 16660 16581 16473 16429 16426>,
			<16739 16672 16595 16477 16431 16428>,
			<17014 16698 16628 16498 16442 16435>,
			<18170 16784 16704 16544 16468 16458>,
			<18170 16784 16704 16544 16468 16458>,
			<18170 16784 16704 16544 16468 16458>;
	};

	qcom,pc-temp-y5-lut {
		qcom,lut-col-legend = <(-10) 0 10 25 40 50>;
		qcom,lut-row-legend = <10000 9800 9600 9400 9200 9000>,
			<8800 8600 8400 8200 8000 7800>,
			<7600 7400 7200 7000 6800 6600>,
			<6400 6200 6000 5800 5600 5400>,
			<5200 5000 4800 4600 4400 4200>,
			<4000 3800 3600 3400 3200 3000>,
			<2800 2600 2400 2200 2000 1800>,
			<1600 1400 1200 1000 900 800>,
			<700 600 500 400 300 200>,
			<100 0>;
		qcom,lut-data = <17348 18390 22978 22453 18938 22031>,
			<17853 18877 22370 22410 19265 22527>,
			<18391 19365 21788 21831 19681 23012>,
			<18928 19797 21246 20994 20109 23438>,
			<19428 20117 20762 20185 20471 23760>,
			<19855 20266 20351 19686 20689 23929>,
			<20291 20236 20003 19351 20815 24220>,
			<20676 20131 19708 18920 20892 24616>,
			<20659 20042 19494 18520 20805 24523>,
			<19881 19928 19356 17999 20482 23924>,
			<18904 19746 19180 17450 20048 23249>,
			<17933 19254 18810 16737 19496 22771>,
			<16991 18368 18249 16028 18786 22317>,
			<16845 17389 17608 15935 18012 21676>,
			<17700 16030 16775 16285 17009 20617>,
			<19063 15145 16054 16560 16413 19454>,
			<21476 15769 15519 16152 16628 18234>,
			<24690 17502 15089 15383 17083 17024>,
			<25531 19229 15388 15238 17287 16725>,
			<24418 21202 18487 15854 17203 17129>,
			<23389 22774 21618 16846 17211 17678>,
			<23342 23420 23009 18596 18472 18352>,
			<23374 23844 23957 20932 20537 19428>,
			<23205 24058 24134 22207 20985 20295>,
			<20656 24225 23989 22959 20345 21183>,
			<17486 24407 23865 23338 19755 21834>,
			<15432 24731 24101 22965 19637 21793>,
			<13250 25252 24641 22104 19640 21322>,
			<12513 25353 24847 21856 19755 20801>,
			<12789 23290 24735 22138 20204 19713>,
			<13140 20577 24615 22333 20596 18735>,
			<13285 19066 24639 22084 20050 18675>,
			<13373 17801 24700 21676 18907 18764>,
			<13510 17388 24877 21678 18686 18934>,
			<13964 18394 25798 22414 19832 19980>,
			<14485 19904 26627 23308 20852 21206>,
			<14736 20913 26432 24106 20852 21538>,
			<14937 21756 25629 25017 20678 21670>,
			<15043 22455 24629 25052 20654 21864>,
			<15119 23134 23209 22173 21107 22350>,
			<15184 23619 21681 19465 21609 23137>,
			<15060 22391 20288 19548 22258 24351>,
			<14497 17809 19314 20534 24072 26426>,
			<13865 15918 19802 22104 26008 28858>,
			<13330 15184 20324 22498 25347 30639>,
			<13378 14822 19817 20990 22183 25451>,
			<13376 14801 19566 21344 21552 24923>,
			<13526 14296 18469 18830 22041 26609>,
			<14042 14593 18296 20111 23983 25077>,
			<14369 14624 20175 23221 24528 22618>,
			<14084 14767 20125 25296 31478 31766>,
			<14227 15553 20090 25721 29620 32286>,
			<12246 15678 19098 24987 29641 31138>,
			<10631 15603 17664 25124 27727 29914>,
			<10631 15603 17664 25124 27727 29914>,
			<10631 15603 17664 25124 27727 29914>;
	};

	qcom,pc-temp-y6-lut {
		qcom,lut-col-legend = <(-10) 0 10 25 40 50>;
		qcom,lut-row-legend = <10000 9800 9600 9400 9200 9000>,
			<8800 8600 8400 8200 8000 7800>,
			<7600 7400 7200 7000 6800 6600>,
			<6400 6200 6000 5800 5600 5400>,
			<5200 5000 4800 4600 4400 4200>,
			<4000 3800 3600 3400 3200 3000>,
			<2800 2600 2400 2200 2000 1800>,
			<1600 1400 1200 1000 900 800>,
			<700 600 500 400 300 200>,
			<100 0>;
		qcom,lut-data = <5521 5198 5049 4959 4928 4919>,
			<5536 5212 5059 4959 4927 4919>,
			<5547 5224 5065 4959 4927 4919>,
			<5555 5234 5069 4958 4927 4919>,
			<5560 5240 5070 4958 4927 4920>,
			<5562 5242 5070 4958 4928 4920>,
			<5560 5240 5069 4958 4928 4920>,
			<5554 5236 5065 4958 4928 4921>,
			<5550 5231 5062 4958 4929 4921>,
			<5544 5227 5059 4959 4929 4921>,
			<5540 5223 5058 4959 4930 4922>,
			<5536 5222 5058 4960 4931 4923>,
			<5532 5221 5058 4962 4932 4923>,
			<5534 5221 5058 4963 4933 4924>,
			<5562 5223 5060 4965 4934 4925>,
			<5585 5226 5063 4968 4935 4926>,
			<5574 5237 5071 4971 4937 4927>,
			<5544 5255 5081 4975 4939 4929>,
			<5519 5259 5084 4980 4943 4931>,
			<5497 5236 5084 4990 4949 4936>,
			<5478 5208 5082 4997 4954 4940>,
			<5464 5190 5069 4989 4949 4936>,
			<5452 5173 5044 4970 4938 4927>,
			<5442 5164 5032 4960 4931 4923>,
			<5434 5157 5025 4955 4928 4921>,
			<5428 5153 5022 4953 4926 4920>,
			<5431 5153 5022 4954 4927 4920>,
			<5440 5153 5023 4954 4927 4921>,
			<5451 5152 5024 4955 4928 4921>,
			<5466 5148 5024 4956 4929 4922>,
			<5483 5145 5025 4959 4931 4923>,
			<5500 5146 5026 4960 4933 4924>,
			<5519 5152 5027 4962 4935 4927>,
			<5540 5160 5028 4964 4936 4928>,
			<5566 5171 5029 4966 4937 4928>,
			<5596 5186 5030 4967 4937 4927>,
			<5626 5203 5031 4965 4935 4926>,
			<5657 5225 5034 4959 4930 4923>,
			<5691 5247 5037 4955 4928 4922>,
			<5728 5269 5040 4953 4928 4922>,
			<5767 5291 5045 4952 4928 4922>,
			<5806 5310 5052 4953 4927 4922>,
			<5846 5328 5062 4955 4927 4922>,
			<5896 5353 5074 4956 4925 4920>,
			<5961 5389 5090 4958 4924 4918>,
			<6047 5435 5099 4961 4927 4921>,
			<6077 5451 5103 4963 4928 4922>,
			<6147 5484 5116 4966 4930 4924>,
			<6237 5530 5137 4971 4935 4929>,
			<6343 5580 5159 4976 4936 4933>,
			<6486 5637 5173 4974 4929 4922>,
			<6824 5728 5207 4976 4930 4923>,
			<7839 5879 5261 4985 4934 4926>,
			<10050 6195 5353 5004 4943 4933>,
			<10050 6195 5353 5004 4943 4933>,
			<10050 6195 5353 5004 4943 4933>;
	};

};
